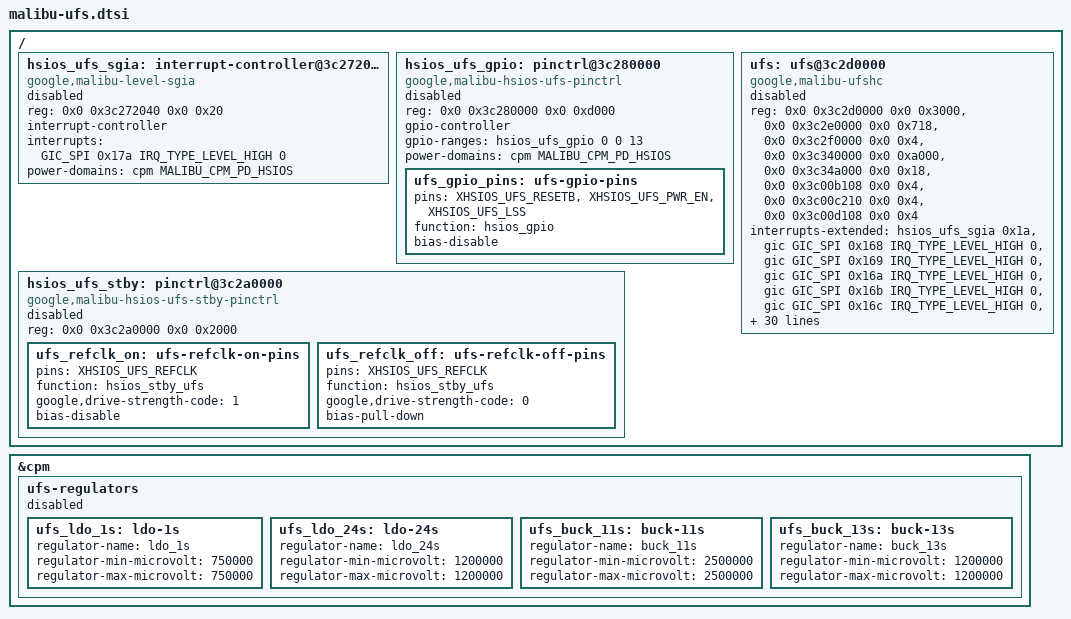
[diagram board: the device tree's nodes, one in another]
// SPDX-License-Identifier: GPL-2.0-only OR BSD-2-Clause

#include <dt-bindings/clock/google,malibu-cpm-io.h>
#include <dt-bindings/gpio/gpio.h>

/ {
	hsios_ufs_sgia: interrupt-controller@3c272040 {
		compatible = "google,malibu-level-sgia";
		reg = <0x0 0x3c272040 0x0 0x20>;
		interrupt-controller;
		#interrupt-cells = <1>;
		#address-cells = <0>;
		interrupts = <GIC_SPI 0x17a IRQ_TYPE_LEVEL_HIGH 0>;
		power-domains = <&cpm MALIBU_CPM_PD_HSIOS>;
		status = "disabled";
	};

	hsios_ufs_gpio: pinctrl@3c280000 {
		compatible = "google,malibu-hsios-ufs-pinctrl";
		reg = <0x0 0x3c280000 0x0 0xd000>;
		gpio-controller;
		#gpio-cells = <2>;
		gpio-ranges = <&hsios_ufs_gpio 0 0 13>;
		power-domains = <&cpm MALIBU_CPM_PD_HSIOS>;
		power-domain-names = "csr";
		status = "disabled";

		ufs_gpio_pins: ufs-gpio-pins {
			pins = "XHSIOS_UFS_RESETB", "XHSIOS_UFS_PWR_EN",
			       "XHSIOS_UFS_LSS";
			function = "hsios_gpio";
			bias-disable;
		};
	};

	hsios_ufs_stby: pinctrl@3c2a0000 {
		compatible = "google,malibu-hsios-ufs-stby-pinctrl";
		reg = <0x0 0x3c2a0000 0x0 0x2000>;
		status = "disabled";

		ufs_refclk_on: ufs-refclk-on-pins {
			pins = "XHSIOS_UFS_REFCLK";
			function = "hsios_stby_ufs";
			google,drive-strength-code = <1>;
			bias-disable;
		};

		ufs_refclk_off: ufs-refclk-off-pins {
			pins = "XHSIOS_UFS_REFCLK";
			function = "hsios_stby_ufs";
			google,drive-strength-code = <0>;
			bias-pull-down;
		};
	};

	/* Keep the host path and ufs0 alias available for ABL PHY fixups. */
	ufs: ufs@3c2d0000 {
		compatible = "google,malibu-ufshc";
		reg = <0x0 0x3c2d0000 0x0 0x3000>,
		      <0x0 0x3c2e0000 0x0 0x718>,
		      <0x0 0x3c2f0000 0x0 0x4>,
		      <0x0 0x3c340000 0x0 0xa000>,
		      <0x0 0x3c34a000 0x0 0x18>,
		      <0x0 0x3c00b108 0x0 0x4>,
		      <0x0 0x3c00c210 0x0 0x4>,
		      <0x0 0x3c00d108 0x0 0x4>;
		reg-names = "hci", "top", "sec", "phy-sram", "subsystem",
			    "psm-hsios", "psm-hci", "psm-phy";
		interrupts-extended =
			<&hsios_ufs_sgia 0x1a>,
			<&gic GIC_SPI 0x168 IRQ_TYPE_LEVEL_HIGH 0>,
			<&gic GIC_SPI 0x169 IRQ_TYPE_LEVEL_HIGH 0>,
			<&gic GIC_SPI 0x16a IRQ_TYPE_LEVEL_HIGH 0>,
			<&gic GIC_SPI 0x16b IRQ_TYPE_LEVEL_HIGH 0>,
			<&gic GIC_SPI 0x16c IRQ_TYPE_LEVEL_HIGH 0>,
			<&gic GIC_SPI 0x16d IRQ_TYPE_LEVEL_HIGH 0>,
			<&gic GIC_SPI 0x16e IRQ_TYPE_LEVEL_HIGH 0>,
			<&gic GIC_SPI 0x16f IRQ_TYPE_LEVEL_HIGH 0>,
			<&gic GIC_SPI 0x170 IRQ_TYPE_LEVEL_HIGH 0>,
			<&gic GIC_SPI 0x171 IRQ_TYPE_LEVEL_HIGH 0>,
			<&gic GIC_SPI 0x172 IRQ_TYPE_LEVEL_HIGH 0>,
			<&gic GIC_SPI 0x173 IRQ_TYPE_LEVEL_HIGH 0>,
			<&gic GIC_SPI 0x174 IRQ_TYPE_LEVEL_HIGH 0>,
			<&gic GIC_SPI 0x175 IRQ_TYPE_LEVEL_HIGH 0>,
			<&gic GIC_SPI 0x176 IRQ_TYPE_LEVEL_HIGH 0>,
			<&gic GIC_SPI 0x177 IRQ_TYPE_LEVEL_HIGH 0>;
		interrupt-names = "hci", "mcq0", "mcq1", "mcq2", "mcq3",
				  "mcq4", "mcq5", "mcq6", "mcq7", "mcq8",
				  "mcq9", "mcq10", "mcq11", "mcq12", "mcq13",
				  "mcq14", "mcq15";
		iommus = <&amb_smmu 0x8000>;
		dma-coherent;
		clocks = <&cpm MALIBU_CPM_CLK_UFS_GPIO_REF>,
			 <&cpm MALIBU_CPM_CLK_UFS_MPHY_REF>,
			 <&cpm MALIBU_CPM_CLK_UFS_CORE>,
			 <&cpm MALIBU_CPM_CLK_UFS_DEEP_H8>;
		clock-names = "gpio-ref", "mphy-ref", "core", "deep-h8";
		resets = <&cpm MALIBU_CPM_RST_UFS_PHY>;
		reset-names = "phy";
		power-domains = <&cpm MALIBU_CPM_PD_UFS_PREP>,
				<&cpm MALIBU_CPM_PD_UFS>;
		power-domain-names = "prep", "core";
		reset-gpios = <&hsios_ufs_gpio 0 GPIO_ACTIVE_LOW>;
		power-gpios = <&hsios_ufs_gpio 8 GPIO_ACTIVE_HIGH>;
		lss-gpios = <&hsios_ufs_gpio 11 GPIO_ACTIVE_HIGH>;
		/* Select these explicitly when starting the device sequence. */
		pinctrl-names = "gpio-prepare", "refclk-on", "refclk-off";
		pinctrl-0 = <&ufs_gpio_pins>;
		pinctrl-1 = <&ufs_refclk_on>;
		pinctrl-2 = <&ufs_refclk_off>;
		vdd0p75-supply = <&ufs_ldo_1s>;
		vdd1p2-supply = <&ufs_ldo_24s>;
		vcc-supply = <&ufs_buck_11s>;
		vccq-supply = <&ufs_buck_13s>;
		status = "disabled";
	};
};

&cpm {
	ufs-regulators {
		status = "disabled";

		ufs_ldo_1s: ldo-1s {
			regulator-name = "ldo_1s";
			regulator-min-microvolt = <750000>;
			regulator-max-microvolt = <750000>;
		};

		ufs_ldo_24s: ldo-24s {
			regulator-name = "ldo_24s";
			regulator-min-microvolt = <1200000>;
			regulator-max-microvolt = <1200000>;
		};

		ufs_buck_11s: buck-11s {
			regulator-name = "buck_11s";
			regulator-min-microvolt = <2500000>;
			regulator-max-microvolt = <2500000>;
		};

		ufs_buck_13s: buck-13s {
			regulator-name = "buck_13s";
			regulator-min-microvolt = <1200000>;
			regulator-max-microvolt = <1200000>;
		};
	};
};
